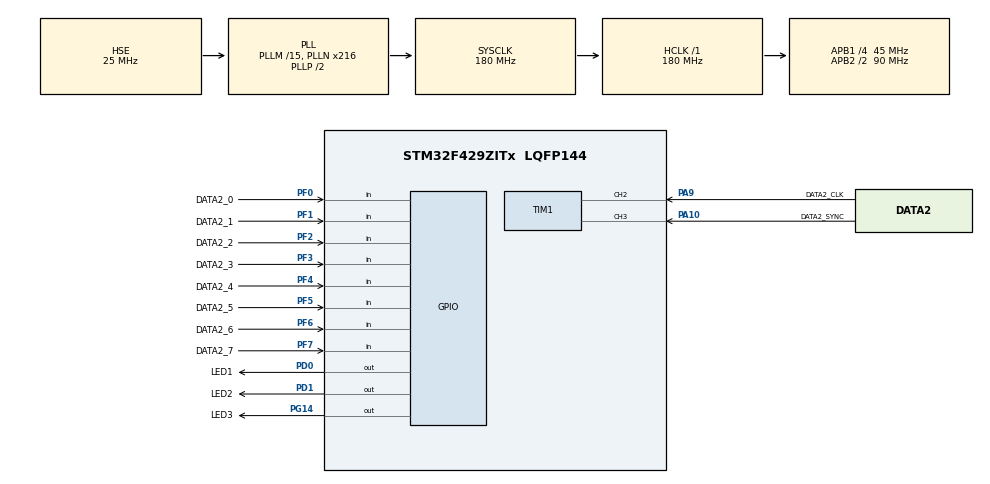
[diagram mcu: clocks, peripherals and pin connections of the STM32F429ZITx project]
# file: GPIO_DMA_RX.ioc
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Dma.Request0=TIM1_CH2
Dma.TIM1_CH2.0.Direction=DMA_PERIPH_TO_MEMORY
Dma.TIM1_CH2.0.FIFOMode=DMA_FIFOMODE_DISABLE
Dma.TIM1_CH2.0.Instance=DMA2_Stream2
Dma.TIM1_CH2.0.MemDataAlignment=DMA_MDATAALIGN_BYTE
Dma.TIM1_CH2.0.MemInc=DMA_MINC_ENABLE
Dma.TIM1_CH2.0.Mode=DMA_NORMAL
Dma.TIM1_CH2.0.PeriphDataAlignment=DMA_PDATAALIGN_BYTE
Dma.TIM1_CH2.0.PeriphInc=DMA_PINC_DISABLE
Dma.TIM1_CH2.0.Priority=DMA_PRIORITY_HIGH
Mcu.Family=STM32F4
Mcu.Name=STM32F429ZITx
Mcu.Package=LQFP144
NVIC.DMA2_Stream2_IRQn=true\:0\:0\:false\:false\:true\:false\:true
NVIC.PriorityGroup=NVIC_PRIORITYGROUP_4
NVIC.TIM1_CC_IRQn=true\:0\:0\:false\:false\:true\:true\:true
PA10.GPIO_Label=DATA2_SYNC
PA10.Signal=S_TIM1_CH3
PA13.Mode=Serial_Wire
PA13.Signal=SYS_JTMS-SWDIO
PA14.Mode=Serial_Wire
PA14.Signal=SYS_JTCK-SWCLK
PA9.GPIO_Label=DATA2_CLK
PA9.GPIO_Speed=GPIO_SPEED_FREQ_VERY_HIGH
PA9.Signal=S_TIM1_CH2
PD0.GPIO_Label=LED1
PD0.GPIO_Speed=GPIO_SPEED_FREQ_VERY_HIGH
PD0.Signal=GPIO_Output
PD1.GPIO_Label=LED2
PD1.GPIO_Speed=GPIO_SPEED_FREQ_VERY_HIGH
PD1.Signal=GPIO_Output
PF0.GPIO_Label=DATA2_0
PF0.GPIO_PuPd=GPIO_PULLDOWN
PF0.Signal=GPIO_Input
PF1.GPIO_Label=DATA2_1
PF1.GPIO_PuPd=GPIO_PULLDOWN
PF1.Signal=GPIO_Input
PF2.GPIO_Label=DATA2_2
PF2.GPIO_PuPd=GPIO_PULLDOWN
PF2.Signal=GPIO_Input
PF3.GPIO_Label=DATA2_3
PF3.GPIO_PuPd=GPIO_PULLDOWN
PF3.Signal=GPIO_Input
PF4.GPIO_Label=DATA2_4
PF4.GPIO_PuPd=GPIO_PULLDOWN
PF4.Signal=GPIO_Input
PF5.GPIO_Label=DATA2_5
PF5.GPIO_PuPd=GPIO_PULLDOWN
PF5.Signal=GPIO_Input
PF6.GPIO_Label=DATA2_6
PF6.GPIO_PuPd=GPIO_PULLDOWN
PF6.Signal=GPIO_Input
PF7.GPIO_Label=DATA2_7
PF7.GPIO_PuPd=GPIO_PULLDOWN
PF7.Signal=GPIO_Input
PG14.GPIO_Label=LED3
PG14.GPIO_Speed=GPIO_SPEED_FREQ_VERY_HIGH
PG14.Signal=GPIO_Output
PH0/OSC_IN.Mode=HSE-External-Oscillator
PH0/OSC_IN.Signal=RCC_OSC_IN
PH1/OSC_OUT.Mode=HSE-External-Oscillator
PH1/OSC_OUT.Signal=RCC_OSC_OUT
ProjectManager.HeapSize=0x200
ProjectManager.StackSize=0x400
ProjectManager.TargetToolchain=MDK-ARM V5.32
RCC.48MHZClocksFreq_Value=90000000
RCC.AHBFreq_Value=180000000
RCC.APB1CLKDivider=RCC_HCLK_DIV4
RCC.APB1Freq_Value=45000000
RCC.APB1TimFreq_Value=90000000
RCC.APB2CLKDivider=RCC_HCLK_DIV2
RCC.APB2Freq_Value=90000000
RCC.APB2TimFreq_Value=180000000
RCC.CortexFreq_Value=180000000
RCC.HCLKFreq_Value=180000000
RCC.HSE_VALUE=25000000
RCC.HSI_VALUE=16000000
RCC.LSE_VALUE=32768
RCC.PLLM=15
RCC.PLLN=216
RCC.PLLSourceVirtual=RCC_PLLSOURCE_HSE
RCC.SYSCLKFreq_VALUE=180000000
RCC.SYSCLKSource=RCC_SYSCLKSOURCE_PLLCLK
RCC.VCOOutputFreq_Value=360000000
SH.S_TIM1_CH2.0=TIM1_CH2,Input_Capture2_from_TI2
SH.S_TIM1_CH3.0=TIM1_CH3,Input_Capture3_from_TI3
TIM1.Channel-Input_Capture2_from_TI2=TIM_CHANNEL_2
TIM1.Channel-Input_Capture3_from_TI3=TIM_CHANNEL_3
TIM1.ICPolarity_CH2=TIM_INPUTCHANNELPOLARITY_FALLING
board=custom

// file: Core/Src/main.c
/* USER CODE BEGIN Header */
/**
  ******************************************************************************
  * @file           : main.c
  * @brief          : Main program body
  ******************************************************************************
  * @attention
  *
  * <h2><center>&copy; Copyright (c) 2021 STMicroelectronics.
  * All rights reserved.</center></h2>
  *
  * This software component is licensed by ST under BSD 3-Clause license,
  * the "License"; You may not use this file except in compliance with the
  * License. You may obtain a copy of the License at:
  *                        opensource.org/licenses/BSD-3-Clause
  *
  ******************************************************************************
  */
/* USER CODE END Header */
#include "main.h"
#include "dma.h"
#include "tim.h"
#include "gpio.h"

/* USER CODE BEGIN Includes */
#include <string.h>
#include <stdio.h>
//#include "RingBuffer.h"
/* USER CODE END Includes */

/* USER CODE BEGIN PV */
uint8_t GPIO_Buffer[GPIO_Buffer_Size]; /*** GPIO DMA (Parallel Input) Buffer ***/
/* USER CODE END PV */

void SystemClock_Config(void);

int main(void)
{

  /* MCU Configuration--------------------------------------------------------*/

  /* Reset of all peripherals, Initializes the Flash interface and the Systick. */
  HAL_Init();

  /* Configure the system clock */
  SystemClock_Config();

  /* Initialize all configured peripherals */
  MX_GPIO_Init();
  MX_DMA_Init();
  MX_TIM1_Init();
  /* USER CODE BEGIN 2 */

	/*** Enable timer input capture for SYNC Pin (PA10) ***/
	HAL_TIM_IC_Start_IT(&htim1, TIM_CHANNEL_3);

  /* USER CODE END 2 */

  /* Infinite loop */
  while (1)
  {

  }
}

void SystemClock_Config(void)
{
  RCC_OscInitTypeDef RCC_OscInitStruct = {0};
  RCC_ClkInitTypeDef RCC_ClkInitStruct = {0};

  /** Configure the main internal regulator output voltage
  */
  __HAL_RCC_PWR_CLK_ENABLE();
  __HAL_PWR_VOLTAGESCALING_CONFIG(PWR_REGULATOR_VOLTAGE_SCALE1);
  /** Initializes the RCC Oscillators according to the specified parameters
  * in the RCC_OscInitTypeDef structure.
  */
  RCC_OscInitStruct.OscillatorType = RCC_OSCILLATORTYPE_HSE;
  RCC_OscInitStruct.HSEState = RCC_HSE_ON;
  RCC_OscInitStruct.PLL.PLLState = RCC_PLL_ON;
  RCC_OscInitStruct.PLL.PLLSource = RCC_PLLSOURCE_HSE;
  RCC_OscInitStruct.PLL.PLLM = 15;
  RCC_OscInitStruct.PLL.PLLN = 216;
  RCC_OscInitStruct.PLL.PLLP = RCC_PLLP_DIV2;
  RCC_OscInitStruct.PLL.PLLQ = 4;
  if (HAL_RCC_OscConfig(&RCC_OscInitStruct) != HAL_OK)
  {
    Error_Handler();
  }
  /** Activate the Over-Drive mode
  */
  if (HAL_PWREx_EnableOverDrive() != HAL_OK)
  {
    Error_Handler();
  }
  /** Initializes the CPU, AHB and APB buses clocks
  */
  RCC_ClkInitStruct.ClockType = RCC_CLOCKTYPE_HCLK|RCC_CLOCKTYPE_SYSCLK
                              |RCC_CLOCKTYPE_PCLK1|RCC_CLOCKTYPE_PCLK2;
  RCC_ClkInitStruct.SYSCLKSource = RCC_SYSCLKSOURCE_PLLCLK;
  RCC_ClkInitStruct.AHBCLKDivider = RCC_SYSCLK_DIV1;
  RCC_ClkInitStruct.APB1CLKDivider = RCC_HCLK_DIV4;
  RCC_ClkInitStruct.APB2CLKDivider = RCC_HCLK_DIV2;

  if (HAL_RCC_ClockConfig(&RCC_ClkInitStruct, FLASH_LATENCY_5) != HAL_OK)
  {
    Error_Handler();
  }
}

void Error_Handler(void)
{
  __disable_irq();
  while (1)
  {
  }
}

/************************ (C) COPYRIGHT STMicroelectronics *****END OF FILE****/
